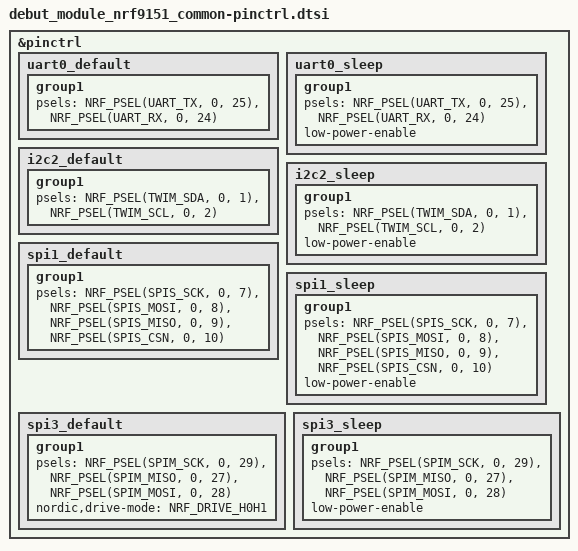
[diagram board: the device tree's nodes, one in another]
/*
 * Copyright (c) 2025 PHYTEC Messtechnik GmbH
 *
 */

&pinctrl {
	uart0_default: uart0_default {
		group1 {
			psels = <NRF_PSEL(UART_TX, 0, 25)>,
				<NRF_PSEL(UART_RX, 0, 24)>;
		};
	};

	uart0_sleep: uart0_sleep {
		group1 {
			psels = <NRF_PSEL(UART_TX, 0, 25)>,
				<NRF_PSEL(UART_RX, 0, 24)>;
			low-power-enable;
		};
	};

	i2c2_default: i2c2_default {
		group1 {
			psels = <NRF_PSEL(TWIM_SDA, 0, 1)>,
				<NRF_PSEL(TWIM_SCL, 0, 2)>;
		};
	};

	i2c2_sleep: i2c2_sleep {
		group1 {
			psels = <NRF_PSEL(TWIM_SDA, 0, 1)>,
				<NRF_PSEL(TWIM_SCL, 0, 2)>;
			low-power-enable;
		};
	};

	spi1_default: spi1_default {
		group1 {
			psels = <NRF_PSEL(SPIS_SCK, 0, 7)>,
				<NRF_PSEL(SPIS_MOSI, 0, 8)>,
				<NRF_PSEL(SPIS_MISO, 0, 9)>,
				<NRF_PSEL(SPIS_CSN, 0, 10)>;
		};
	};

	spi1_sleep: spi1_sleep {
		group1 {
			psels = <NRF_PSEL(SPIS_SCK, 0, 7)>,
				<NRF_PSEL(SPIS_MOSI, 0, 8)>,
				<NRF_PSEL(SPIS_MISO, 0, 9)>,
				<NRF_PSEL(SPIS_CSN, 0, 10)>;
			low-power-enable;
		};
	};

	spi3_default: spi3_default {
		group1 {
			psels = <NRF_PSEL(SPIM_SCK, 0, 29)>,
				<NRF_PSEL(SPIM_MISO, 0, 27)>,
				<NRF_PSEL(SPIM_MOSI, 0, 28)>;
			nordic,drive-mode = <NRF_DRIVE_H0H1>;
		};
	};

	spi3_sleep: spi3_sleep {
		group1 {
			psels = <NRF_PSEL(SPIM_SCK, 0, 29)>,
				<NRF_PSEL(SPIM_MISO, 0, 27)>,
				<NRF_PSEL(SPIM_MOSI, 0, 28)>;
			low-power-enable;
		};
	};
};
